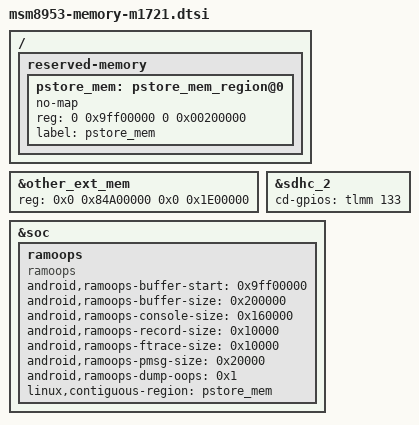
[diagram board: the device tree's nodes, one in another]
/*
 * Copyright (c) 2017, The Linux Foundation. All rights reserved.
 *
 * This program is free software; you can redistribute it and/or modify
 * it under the terms of the GNU General Public License version 2 and
 * only version 2 as published by the Free Software Foundation.
 *
 * This program is distributed in the hope that it will be useful,
 * but WITHOUT ANY WARRANTY; without even the implied warranty of
 * MERCHANTABILITY or FITNESS FOR A PARTICULAR PURPOSE.  See the
 * GNU General Public License for more details.
 */

&other_ext_mem {
    reg = <0x0 0x84A00000 0x0 0x1E00000>;
};

&sdhc_2 {
    cd-gpios = <&tlmm 133 0>;
};

/ {
	reserved-memory {
		pstore_mem: pstore_mem_region@0 {
			no-map;
			reg = <0 0x9ff00000 0 0x00200000>;
			label = "pstore_mem";
		};
	};
};

&soc {
	ramoops {
		compatible = "ramoops";
		status = "ok";

		android,ramoops-buffer-start = <0x9ff00000>;
		android,ramoops-buffer-size =  <0x200000>;
		android,ramoops-console-size = <0x160000>;
		android,ramoops-record-size = <0x10000>;
		android,ramoops-ftrace-size = <0x10000>;
		android,ramoops-pmsg-size = <0x20000>;
		android,ramoops-dump-oops = <0x1>;

		linux,contiguous-region = <&pstore_mem>;
	};
};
